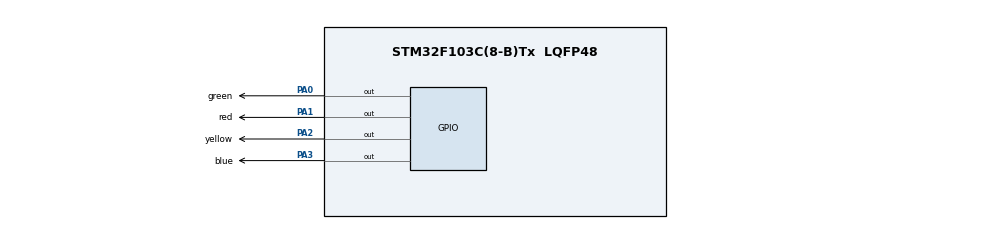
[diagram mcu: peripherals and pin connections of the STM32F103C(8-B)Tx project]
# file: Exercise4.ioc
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FREERTOS.Tasks01=defaultTask,0,128,StartDefaultTask,Default,NULL,Dynamic,NULL,NULL;Green_Led_Flash,0,128,GreenTask,Default,NULL,Dynamic,NULL,NULL;Red_Led_Flash,0,128,RedTask,Default,NULL,Dynamic,NULL,NULL
Mcu.Family=STM32F1
Mcu.Name=STM32F103C(8-B)Tx
Mcu.Package=LQFP48
NVIC.PriorityGroup=NVIC_PRIORITYGROUP_4
PA0-WKUP.GPIO_Label=green
PA0-WKUP.Signal=GPIO_Output
PA1.GPIO_Label=red
PA1.Signal=GPIO_Output
PA2.GPIO_Label=yellow
PA2.Signal=GPIO_Output
PA3.GPIO_Label=blue
PA3.Signal=GPIO_Output
PD0-OSC_IN.Mode=HSE-External-Oscillator
PD0-OSC_IN.Signal=RCC_OSC_IN
PD1-OSC_OUT.Mode=HSE-External-Oscillator
PD1-OSC_OUT.Signal=RCC_OSC_OUT
ProjectManager.HeapSize=0x200
ProjectManager.StackSize=0x400
ProjectManager.TargetToolchain=STM32CubeIDE
RCC.APB1Freq_Value=8000000
RCC.APB2Freq_Value=8000000
VP_FREERTOS_VS_CMSIS_V1.Mode=CMSIS_V1
VP_SYS_VS_ND.Mode=No_Debug
VP_TIM4_VS_ClockSourceINT.Mode=Internal
board=custom

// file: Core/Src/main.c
/* USER CODE BEGIN Header */
/**
  ******************************************************************************
  * @file           : main.c
  * @brief          : Main program body
  ******************************************************************************
  * @attention
  *
  * Copyright (c) 2024 STMicroelectronics.
  * All rights reserved.
  *
  * This software is licensed under terms that can be found in the LICENSE file
  * in the root directory of this software component.
  * If no LICENSE file comes with this software, it is provided AS-IS.
  *
  ******************************************************************************
  */
/* USER CODE END Header */
#include "main.h"
#include "cmsis_os.h"

TIM_HandleTypeDef htim4;

osThreadId defaultTaskHandle;
osThreadId Green_Led_FlashHandle;
osThreadId Red_Led_FlashHandle;

void SystemClock_Config(void);
static void MX_GPIO_Init(void);
static void MX_TIM4_Init(void);
void StartDefaultTask(void const * argument);
void GreenTask(void const * argument);
void RedTask(void const * argument);

int main(void)
{

  /* MCU Configuration--------------------------------------------------------*/

  /* Reset of all peripherals, Initializes the Flash interface and the Systick. */
  HAL_Init();

  /* Configure the system clock */
  SystemClock_Config();

  /* Initialize all configured peripherals */
  MX_GPIO_Init();
  MX_TIM4_Init();

  /* Create the thread(s) */
  /* definition and creation of defaultTask */
  osThreadDef(defaultTask, StartDefaultTask, osPriorityNormal, 0, 128);
  defaultTaskHandle = osThreadCreate(osThread(defaultTask), NULL);

  /* definition and creation of Green_Led_Flash */
  osThreadDef(Green_Led_Flash, GreenTask, osPriorityNormal, 0, 128);
  Green_Led_FlashHandle = osThreadCreate(osThread(Green_Led_Flash), NULL);

  /* definition and creation of Red_Led_Flash */
  osThreadDef(Red_Led_Flash, RedTask, osPriorityNormal, 0, 128);
  Red_Led_FlashHandle = osThreadCreate(osThread(Red_Led_Flash), NULL);

  /* Start scheduler */
  osKernelStart();

  /* We should never get here as control is now taken by the scheduler */

  /* Infinite loop */
  while (1)
  {

  }
}

void SystemClock_Config(void)
{
  RCC_OscInitTypeDef RCC_OscInitStruct = {0};
  RCC_ClkInitTypeDef RCC_ClkInitStruct = {0};

  /** Initializes the RCC Oscillators according to the specified parameters
  * in the RCC_OscInitTypeDef structure.
  */
  RCC_OscInitStruct.OscillatorType = RCC_OSCILLATORTYPE_HSI;
  RCC_OscInitStruct.HSIState = RCC_HSI_ON;
  RCC_OscInitStruct.HSICalibrationValue = RCC_HSICALIBRATION_DEFAULT;
  RCC_OscInitStruct.PLL.PLLState = RCC_PLL_NONE;
  if (HAL_RCC_OscConfig(&RCC_OscInitStruct) != HAL_OK)
  {
    Error_Handler();
  }

  /** Initializes the CPU, AHB and APB buses clocks
  */
  RCC_ClkInitStruct.ClockType = RCC_CLOCKTYPE_HCLK|RCC_CLOCKTYPE_SYSCLK
                              |RCC_CLOCKTYPE_PCLK1|RCC_CLOCKTYPE_PCLK2;
  RCC_ClkInitStruct.SYSCLKSource = RCC_SYSCLKSOURCE_HSI;
  RCC_ClkInitStruct.AHBCLKDivider = RCC_SYSCLK_DIV1;
  RCC_ClkInitStruct.APB1CLKDivider = RCC_HCLK_DIV1;
  RCC_ClkInitStruct.APB2CLKDivider = RCC_HCLK_DIV1;

  if (HAL_RCC_ClockConfig(&RCC_ClkInitStruct, FLASH_LATENCY_0) != HAL_OK)
  {
    Error_Handler();
  }
}

static void MX_TIM4_Init(void)
{

  TIM_ClockConfigTypeDef sClockSourceConfig = {0};
  TIM_MasterConfigTypeDef sMasterConfig = {0};

  htim4.Instance = TIM4;
  htim4.Init.Prescaler = 0;
  htim4.Init.CounterMode = TIM_COUNTERMODE_UP;
  htim4.Init.Period = 65535;
  htim4.Init.ClockDivision = TIM_CLOCKDIVISION_DIV1;
  htim4.Init.AutoReloadPreload = TIM_AUTORELOAD_PRELOAD_DISABLE;
  if (HAL_TIM_Base_Init(&htim4) != HAL_OK)
  {
    Error_Handler();
  }
  sClockSourceConfig.ClockSource = TIM_CLOCKSOURCE_INTERNAL;
  if (HAL_TIM_ConfigClockSource(&htim4, &sClockSourceConfig) != HAL_OK)
  {
    Error_Handler();
  }
  sMasterConfig.MasterOutputTrigger = TIM_TRGO_RESET;
  sMasterConfig.MasterSlaveMode = TIM_MASTERSLAVEMODE_DISABLE;
  if (HAL_TIMEx_MasterConfigSynchronization(&htim4, &sMasterConfig) != HAL_OK)
  {
    Error_Handler();
  }

}

static void MX_GPIO_Init(void)
{
  GPIO_InitTypeDef GPIO_InitStruct = {0};

  /* GPIO Ports Clock Enable */
  __HAL_RCC_GPIOD_CLK_ENABLE();
  __HAL_RCC_GPIOA_CLK_ENABLE();

  /*Configure GPIO pin Output Level */
  HAL_GPIO_WritePin(GPIOA, green_Pin|red_Pin|yellow_Pin|blue_Pin, GPIO_PIN_RESET);

  /*Configure GPIO pins : green_Pin red_Pin yellow_Pin blue_Pin */
  GPIO_InitStruct.Pin = green_Pin|red_Pin|yellow_Pin|blue_Pin;
  GPIO_InitStruct.Mode = GPIO_MODE_OUTPUT_PP;
  GPIO_InitStruct.Pull = GPIO_NOPULL;
  GPIO_InitStruct.Speed = GPIO_SPEED_FREQ_LOW;
  HAL_GPIO_Init(GPIOA, &GPIO_InitStruct);

}

void StartDefaultTask(void const * argument)
{
  for(;;)
  {
    osDelay(1);
  }
}

void GreenTask(void const * argument)
{
  /* USER CODE BEGIN GreenTask */
  /* Infinite loop */
  for(;;)
  {
    HAL_GPIO_WritePin(GPIOA, blue_Pin, GPIO_PIN_SET);

	  for (int i = 0; i < 80; ++i) {
	  		  HAL_GPIO_TogglePin(GPIOA,green_Pin);
	  		  osDelay(50);  // 50ms delay = 20 Hz toggling
	  	  }

	  	  HAL_GPIO_WritePin(GPIOA, green_Pin, GPIO_PIN_RESET);
	  	  HAL_GPIO_WritePin(GPIOA, blue_Pin, GPIO_PIN_RESET);

	  	  osDelay(6000);
  }
  /* USER CODE END GreenTask */
}

void RedTask(void const * argument)
{
  /* USER CODE BEGIN RedTask */
  /* Infinite loop */
  for(;;)
  {
	  // 1. Turn the Orange LED on (Task is active)
	  		  HAL_GPIO_WritePin(GPIOA, yellow_Pin, GPIO_PIN_SET);

	  		   // 2. Flash the Red LED at 20 Hz for 0.5 seconds (Task execution)
	  		   for (int i = 0; i < 10; ++i) {
	  			   HAL_GPIO_TogglePin(GPIOA, red_Pin);
	  			   osDelay(50);  // 50ms delay = 20 Hz toggling
	  		   }

	  		   // 3. Turn off both LEDs (Task complete)
	  		   HAL_GPIO_WritePin(GPIOA, red_Pin, GPIO_PIN_RESET);
	  		   HAL_GPIO_WritePin(GPIOA, yellow_Pin, GPIO_PIN_RESET);

	  		   // 4. Suspend task for 1.5 seconds (2 - 0.5 = 1.5 seconds)
	  		   osDelay(1500);;
  }
  /* USER CODE END RedTask */
}

void Error_Handler(void)
{
  __disable_irq();
  while (1)
  {
  }
}
